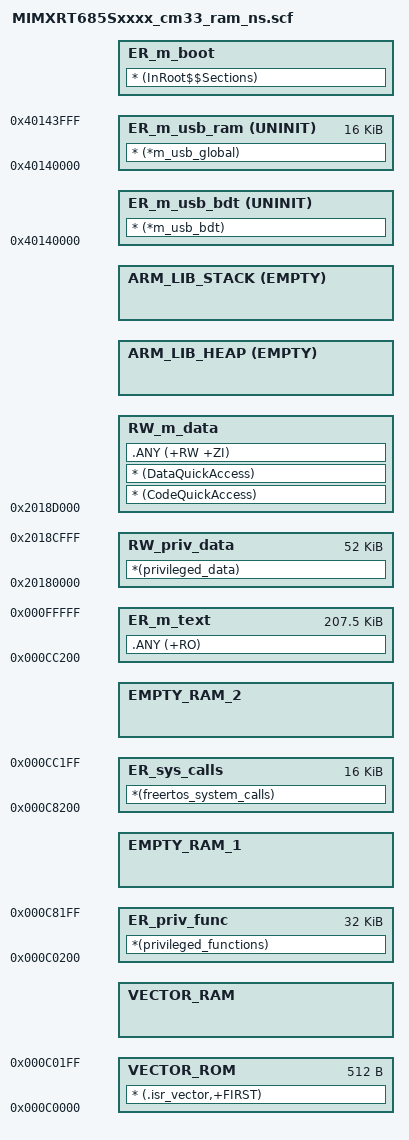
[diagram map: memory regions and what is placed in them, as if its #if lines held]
#!armclang --target=arm-arm-none-eabi -march=armv8-m.main -E -x c
/*
** ###################################################################
**     Processors:          MIMXRT685SFAWBR_cm33
**                          MIMXRT685SFFOB_cm33
**                          MIMXRT685SFVKB_cm33
**
**     Compiler:            Keil ARM C/C++ Compiler
**     Reference manual:    MIMXRT685 User manual Rev. 0.95 11 November 2019
**     Version:             rev. 1.0, 2018-06-19
**     Build:               b201029
**
**     Abstract:
**         Linker file for the Keil ARM C/C++ Compiler
**
**     Copyright 2016 Freescale Semiconductor, Inc.
**     Copyright 2016-2020 NXP
**     All rights reserved.
**
**     SPDX-License-Identifier: BSD-3-Clause
**
**     http:                 www.nxp.com
**     mail:                 support@nxp.com
**
** ###################################################################
*/


/* USB BDT size */
#define usb_bdt_size                   0x0
/* Sizes */
#if (defined(__stack_size__))
  #define Stack_Size                   __stack_size__
#else
  #define Stack_Size                   0x0400
#endif

#if (defined(__heap_size__))
  #define Heap_Size                    __heap_size__
#else
  #define Heap_Size                    0x0400
#endif

/* The SRAM region [0x10000-0x1BFFF] is reserved for ROM code. */
/* The SRAM region [0x0-0xFFFF], [0x1C000-0x1FFFF] is reserved for app-specific use cases. */
/* The SRAM region [0x20000-0x7FFFF] is reserved for Non-cached shared memory between M33 and DSP. */
#define  m_flash_image_start           0x08041000

#define  m_interrupts_start            0x000C0000
#define  m_interrupts_size             0x00000200

#define  priv_func_start               0x000C0200
#define  priv_func_size                0x00008000

#define  sys_calls_start               0x000C8200
#define  sys_calls_size                0x00004000

#define  m_text_start                  0x000CC200
#define  m_text_size                   0x00033E00

#define  priv_data_start               0x20180000
#define  priv_data_size                0x0000D000

#define  m_data_start                  0x2018D000
#define  m_data_size                   0x00073000

#define  m_usb_sram_start              0x40140000
#define  m_usb_sram_size               0x00004000

LR_m_interrupts m_flash_image_start m_interrupts_size+m_text_size {
  VECTOR_ROM m_interrupts_start m_interrupts_size {
    * (.isr_vector,+FIRST)
  }
  VECTOR_RAM +0 FILL 0x0 priv_func_start-ImageLimit(VECTOR_ROM){
  }

  ER_priv_func priv_func_start priv_func_size {
    *(privileged_functions)
  }
  EMPTY_RAM_1 +0 FILL 0x0 sys_calls_start-ImageLimit(ER_priv_func){
  }

  ER_sys_calls sys_calls_start sys_calls_size {
    *(freertos_system_calls)
  }

  EMPTY_RAM_2 +0 FILL 0x0 m_text_start-ImageLimit(ER_sys_calls) {
  }

  ER_m_text m_text_start m_text_size {
    .ANY (+RO)
  }

  RW_priv_data priv_data_start priv_data_size { ; privileged data
    *(privileged_data)
  }
  RW_m_data m_data_start ALIGN 4 m_data_size-Stack_Size-Heap_Size { ; RW data
    * (CodeQuickAccess)
    * (DataQuickAccess)
    .ANY (+RW +ZI)
  }

  ARM_LIB_HEAP +0 EMPTY Heap_Size {    ; Heap region growing up
  }
  ARM_LIB_STACK m_data_start+m_data_size EMPTY -Stack_Size { ; Stack region growing down
  }

  ER_m_usb_bdt m_usb_sram_start UNINIT usb_bdt_size {
    * (*m_usb_bdt)
  }

  ER_m_usb_ram (m_usb_sram_start + usb_bdt_size) UNINIT (m_usb_sram_size - usb_bdt_size) {
    * (*m_usb_global)
  }
}

LR_m_boot +0 {
  ER_m_boot +0 { ; load address = execution address
    * (InRoot$$Sections)
  }
}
